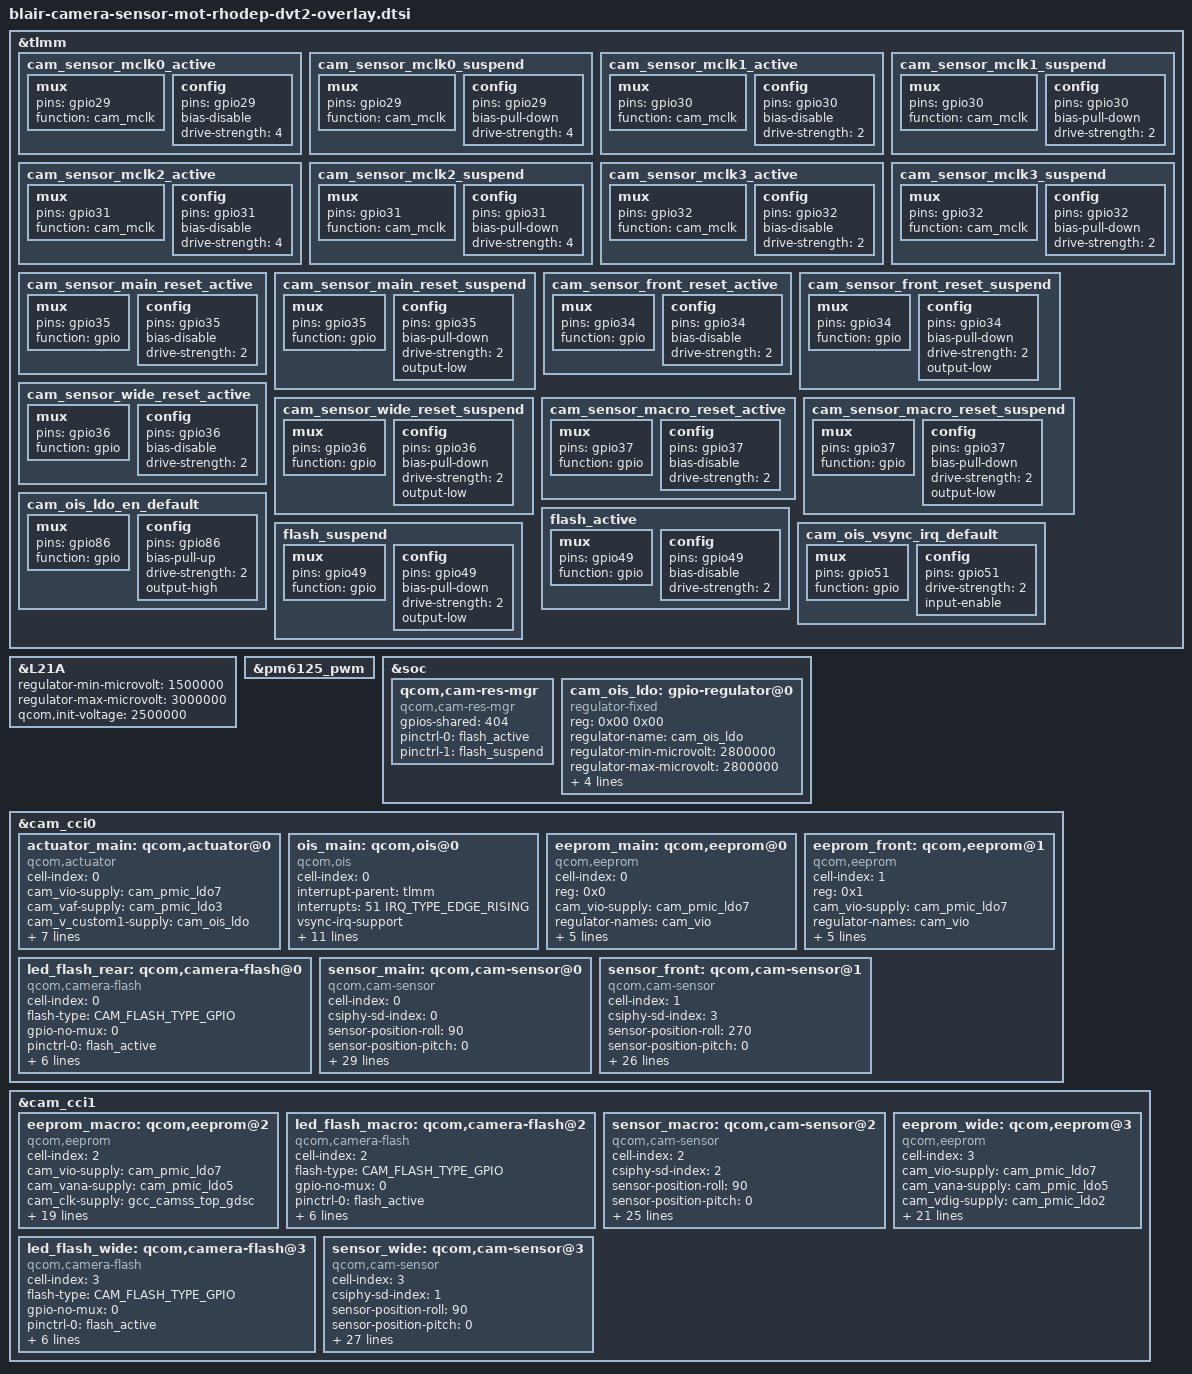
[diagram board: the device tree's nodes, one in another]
#include <dt-bindings/clock/qcom,gcc-blair.h>
#include <dt-bindings/msm/msm-camera.h>

/delete-node/ &cam_sensor_mclk0_active;
/delete-node/ &cam_sensor_mclk1_active;
/delete-node/ &cam_sensor_mclk2_active;
/delete-node/ &cam_sensor_mclk3_active;
/delete-node/ &cam_sensor_main_reset_active;
/delete-node/ &cam_sensor_front_reset_active;
/delete-node/ &cam_sensor_macro_reset_active;
/delete-node/ &cam_sensor_wide_reset_active;
/delete-node/ &flash_active;
/delete-node/ &cam_sensor_mclk0_suspend;
/delete-node/ &cam_sensor_mclk1_suspend;
/delete-node/ &cam_sensor_mclk2_suspend;
/delete-node/ &cam_sensor_mclk3_suspend;
/delete-node/ &cam_sensor_main_reset_suspend;
/delete-node/ &cam_sensor_front_reset_suspend;
/delete-node/ &cam_sensor_macro_reset_suspend;
/delete-node/ &cam_sensor_wide_reset_suspend;
/delete-node/ &flash_suspend;
/delete-node/ &cam_ois_ldo_en_default;
/delete-node/ &cam_ois_ldo;
/delete-node/ &actuator_main;
/delete-node/ &ois_main;
/delete-node/ &eeprom_main;
/delete-node/ &eeprom_front;
/delete-node/ &led_flash_rear;
/delete-node/ &sensor_main;
/delete-node/ &sensor_front;
/delete-node/ &eeprom_macro;
/delete-node/ &led_flash_macro;
/delete-node/ &sensor_macro;
/delete-node/ &eeprom_wide;
/delete-node/ &led_flash_wide;
/delete-node/ &sensor_wide;
/delete-node/ &cam_ois_vsync_irq_default;

&tlmm {
	cam_sensor_mclk0_active: cam_sensor_mclk0_active {
		mux {
			pins = "gpio29";
			function = "cam_mclk";
		};

		config {
			pins = "gpio29";
			bias-disable; /* No PULL */
			drive-strength = <4>; /* 2 MA */
		};
	};

	cam_sensor_mclk0_suspend: cam_sensor_mclk0_suspend {
		mux {
			pins = "gpio29";
			function = "cam_mclk";
		};

		config {
			pins = "gpio29";
			bias-pull-down; /* PULL DOWN */
			drive-strength = <4>; /* 2 MA */
		};
	};

	cam_sensor_mclk1_active: cam_sensor_mclk1_active {
		mux {
			pins = "gpio30";
			function = "cam_mclk";
		};

		config {
			pins = "gpio30";
			bias-disable; /* No PULL */
			drive-strength = <2>;
		};
	};

	cam_sensor_mclk1_suspend: cam_sensor_mclk1_suspend {
		mux {
			pins = "gpio30";
			function = "cam_mclk";
		};

		config {
			pins = "gpio30";
			bias-pull-down; /* PULL DOWN */
			drive-strength = <2>;
		};
	};

	cam_sensor_mclk2_active: cam_sensor_mclk2_active {
		mux {
			pins = "gpio31";
			function = "cam_mclk";
		};

		config {
			pins = "gpio31";
			bias-disable; /* No PULL */
			drive-strength = <4>;
		};
	};

	cam_sensor_mclk2_suspend: cam_sensor_mclk2_suspend {
		mux {
			pins = "gpio31";
			function = "cam_mclk";
		};

		config {
			pins = "gpio31";
			bias-pull-down; /* PULL DOWN */
			drive-strength = <4>;
		};
	};

	cam_sensor_mclk3_active: cam_sensor_mclk3_active {
		mux {
			pins = "gpio32";
			function = "cam_mclk";
		};

		config {
			pins = "gpio32";
			bias-disable; /* No PULL */
			drive-strength = <2>;
		};
	};

	cam_sensor_mclk3_suspend: cam_sensor_mclk3_suspend {
		mux {
			pins = "gpio32";
			function = "cam_mclk";
		};

		config {
			pins = "gpio32";
			bias-pull-down; /* PULL DOWN */
			drive-strength = <2>;
		};
	};

	cam_sensor_main_reset_active: cam_sensor_main_reset_active {
		mux {
			pins = "gpio35";
			function = "gpio";
		};

		config {
			pins = "gpio35";
			bias-disable; /* No PULL */
			drive-strength = <2>; /* 2 MA */
		};
	};

	cam_sensor_main_reset_suspend: cam_sensor_main_reset_suspend {
		mux {
			pins = "gpio35";
			function = "gpio";
		};

		config {
			pins = "gpio35";
			bias-pull-down; /* PULL DOWN */
			drive-strength = <2>; /* 2 MA */
			output-low;
		};
	};

	cam_sensor_front_reset_active: cam_sensor_front_reset_active {
		mux {
			pins = "gpio34";
			function = "gpio";
		};

		config {
			pins = "gpio34";
			bias-disable; /* No PULL */
			drive-strength = <2>; /* 2 MA */
		};
	};

	cam_sensor_front_reset_suspend: cam_sensor_front_reset_suspend {
		mux {
			pins = "gpio34";
			function = "gpio";
		};

		config {
			pins = "gpio34";
			bias-pull-down; /* PULL DOWN */
			drive-strength = <2>; /* 2 MA */
			output-low;
		};
	};

	cam_sensor_wide_reset_active: cam_sensor_wide_reset_active {
		mux {
			pins = "gpio36";
			function = "gpio";
		};

		config {
			pins = "gpio36";
			bias-disable; /* No PULL */
			drive-strength = <2>; /* 2 MA */
		};
	};

	cam_sensor_wide_reset_suspend: cam_sensor_wide_reset_suspend {
		mux {
			pins = "gpio36";
			function = "gpio";
		};

		config {
			pins = "gpio36";
			bias-pull-down; /* PULL DOWN */
			drive-strength = <2>; /* 2 MA */
			output-low;
		};
	};

	cam_sensor_macro_reset_active: cam_sensor_macro_reset_active {
		mux {
			pins = "gpio37";
			function = "gpio";
		};

		config {
			pins = "gpio37";
			bias-disable; /* No PULL */
			drive-strength = <2>; /* 2 MA */
		};
	};

	cam_sensor_macro_reset_suspend: cam_sensor_macro_reset_suspend {
		mux {
			pins = "gpio37";
			function = "gpio";
		};

		config {
			pins = "gpio37";
			bias-pull-down; /* PULL DOWN */
			drive-strength = <2>; /* 2 MA */
			output-low;
		};
	};
	cam_ois_ldo_en_default: cam_ois_ldo_en_default {
		mux {
			pins = "gpio86";
			function = "gpio";
		};
		config {
			pins = "gpio86";
			bias-pull-up; /* NO PULL */
			drive-strength = <2>; /* 2 MA */
			output-high;
		};
	};

	flash_active: flash_active {
		/* MCLK 0*/
		mux {
			pins = "gpio49";
			function = "gpio";
		};

		config {
			pins = "gpio49";
			bias-disable; /* No PULL */
			drive-strength = <2>; /* 2 MA */
		};
	};

	flash_suspend: flash_suspend {
		/* MCLK 0*/
		mux {
			pins = "gpio49";
			function = "gpio";
		};

		config {
			pins = "gpio49";
			bias-pull-down; /* PULL DOWN */
			drive-strength = <2>; /* 2 MA */
			output-low;
		};
	};

	cam_ois_vsync_irq_default: cam_ois_vsync_irq_default {
		mux {
			pins = "gpio51";
			function = "gpio";
		};
		config {
			pins = "gpio51";
			drive-strength = <2>;
			input-enable;
		};
	};
};

&L21A{
	regulator-min-microvolt = <1500000>;
	regulator-max-microvolt = <3000000>;
	qcom,init-voltage = <2500000>;
	status = "okay";
};

&pm6125_pwm {
 status = "ok";
};

&soc {
	qcom,cam-res-mgr {
		compatible = "qcom,cam-res-mgr";
		status = "ok";
		gpios-shared = <404>;
		pinctrl-names = "flash_active", "flash_suspend";
		pinctrl-0 = <&flash_active>;
		pinctrl-1 = <&flash_suspend>;
	};

	cam_ois_ldo: gpio-regulator@0{
		compatible = "regulator-fixed";
		reg = <0x00 0x00>;
		regulator-name = "cam_ois_ldo";
		regulator-min-microvolt = <2800000>;
		regulator-max-microvolt = <2800000>;
		regulator-enable-ramp-delay = <233>;
		enable-active-high;
		gpio = <&tlmm 86 0>;
		pinctrl-names = "default";
		pinctrl-0 = <&cam_ois_ldo_en_default>;
	};
};

&cam_cci0 {
	actuator_main: qcom,actuator@0 {
		cell-index = <0>;
		compatible = "qcom,actuator";
		cam_vio-supply = <&cam_pmic_ldo7>;
		cam_vaf-supply = <&cam_pmic_ldo3>;
		cam_v_custom1-supply = <&cam_ois_ldo>;
		regulator-names = "cam_vio", "cam_vaf", "cam_v_custom1";
		rgltr-cntrl-support;
		rgltr-min-voltage = <1800000 2800000 2800000>;
		rgltr-max-voltage = <1805000 2805000 2805000>;
		rgltr-load-current = <120000 100000 100000>;
		cci-master = <1>;
		status = "ok";
	};

	ois_main: qcom,ois@0 {
		cell-index = <0>;
		compatible = "qcom,ois";
		interrupt-parent = <&tlmm>;
		interrupts = <51 IRQ_TYPE_EDGE_RISING>;
		vsync-irq-support;
		pinctrl-names = "default";
		pinctrl-0 = <&cam_ois_vsync_irq_default>;
		cam_vio-supply = <&cam_pmic_ldo7>;
		cam_vaf-supply = <&cam_pmic_ldo3>;
		cam_v_custom1-supply = <&cam_ois_ldo>;
		regulator-names = "cam_vio", "cam_vaf", "cam_v_custom1";
		rgltr-cntrl-support;
		rgltr-min-voltage = <1800000 2800000 2800000>;
		rgltr-max-voltage = <1805000 2805000 2800000>;
		rgltr-load-current = <120000 100000 100000>;
		cci-master = <1>;
		status = "ok";
	};

	eeprom_main: qcom,eeprom@0 {
		cell-index = <0>;
		reg = <0x0>;
		compatible = "qcom,eeprom";
		cam_vio-supply = <&cam_pmic_ldo7>;
		regulator-names = "cam_vio";
		rgltr-cntrl-support;
		rgltr-min-voltage = <1800000>;
		rgltr-max-voltage = <1805000>;
		rgltr-load-current = <120000>;
		cci-master = <1>;
		status = "ok";
	};

	eeprom_front: qcom,eeprom@1 {
		cell-index = <1>;
		reg = <0x1>;
		compatible = "qcom,eeprom";
		cam_vio-supply = <&cam_pmic_ldo7>;
		regulator-names = "cam_vio";
		rgltr-cntrl-support;
		rgltr-min-voltage = <1800000>;
		rgltr-max-voltage = <1805000>;
		rgltr-load-current = <3000>;
		cci-master = <0>;
		status = "ok";
	};

	led_flash_rear: qcom,camera-flash@0 {
		cell-index = <0>;
		compatible = "qcom,camera-flash";
		flash-type = <CAM_FLASH_TYPE_GPIO>;
		gpio-no-mux = <0>;
		pinctrl-names = "cam_default", "cam_suspend";
		pinctrl-0 = <&flash_active>;
		pinctrl-1 = <&flash_suspend>;
		gpios = <&tlmm 49 0>;
		gpio-custom1 = <0>;
		gpio-req-tbl-num = <0>;
		gpio-req-tbl-flags = <0>;
		gpio-req-tbl-label = "CUSTOM_GPIO1";
		status = "ok";
	};

	sensor_main: qcom,cam-sensor@0 {
		cell-index = <0>;
		compatible = "qcom,cam-sensor";
		csiphy-sd-index = <0>;
		sensor-position-roll = <90>;
		sensor-position-pitch = <0>;
		sensor-position-yaw = <180>;
		actuator-src = <&actuator_main>;
		eeprom-src = <&eeprom_main>;
		ois-src = <&ois_main>;
		led-flash-src = <&led_flash_rear>;
		cam_vio-supply = <&cam_pmic_ldo7>;
		cam_vana-supply = <&cam_pmic_ldo4>;
		cam_vdig-supply = <&cam_pmic_ldo1>;
		cam_clk-supply = <&gcc_camss_top_gdsc>;
		regulator-names = "cam_vio", "cam_vana", "cam_vdig",
			"cam_clk";
		rgltr-cntrl-support;
		rgltr-min-voltage = <1800000 2800000 1050000 0>;
		rgltr-max-voltage = <1805000 2805000 1100000 0>;
		rgltr-load-current = <120000 80000 1200000 0>;
		gpio-no-mux = <0>;
		pinctrl-names = "cam_default", "cam_suspend";
		pinctrl-0 = <&cam_sensor_mclk1_active
				&cam_sensor_main_reset_active>;
		pinctrl-1 = <&cam_sensor_mclk1_suspend
				&cam_sensor_main_reset_suspend>;
		gpios = <&tlmm 30 0>,
			<&tlmm 35 0>;
		gpio-reset = <1>;
		gpio-req-tbl-num = <0 1>;
		gpio-req-tbl-flags = <1 0>;
		gpio-req-tbl-label = "CAMIF_MCLK1",
					"CAM_RM_RST";
		cci-master = <1>;
		status = "ok";
		clocks = <&gcc GCC_CAMSS_MCLK1_CLK>;
		clock-names = "cam_clk";
		clock-cntl-level = "turbo";
		clock-rates = <24000000>;
	};
	sensor_front: qcom,cam-sensor@1 {
		cell-index = <1>;
		compatible = "qcom,cam-sensor";
		csiphy-sd-index = <3>;
		sensor-position-roll = <270>;
		sensor-position-pitch = <0>;
		sensor-position-yaw = <0>;
		eeprom-src = <&eeprom_front>;
		cam_vio-supply = <&cam_pmic_ldo7>;
		cam_vana-supply = <&cam_pmic_ldo6>;
		cam_vdig-supply = <&L21A>;
		cam_clk-supply = <&gcc_camss_top_gdsc>;
		regulator-names = "cam_vio", "cam_vana", "cam_vdig",
			"cam_clk";
		rgltr-cntrl-support;
		rgltr-min-voltage = <1800000 2800000 2500000 0>;
		rgltr-max-voltage = <1805000 2805000 2500000 0>;
		rgltr-load-current = <120000 80000 2500000 0>;
		gpio-no-mux = <0>;
		pinctrl-names = "cam_default", "cam_suspend";
		pinctrl-0 = <&cam_sensor_mclk0_active
				&cam_sensor_front_reset_active>;
		pinctrl-1 = <&cam_sensor_mclk0_suspend
				&cam_sensor_front_reset_suspend>;
		gpios = <&tlmm 31 0>,
			<&tlmm 34 0>;
		gpio-reset = <1>;
		gpio-req-tbl-num = <0 1>;
		gpio-req-tbl-flags = <1 0>;
		gpio-req-tbl-label = "CAMIF_MCLK0",
					"CAM_FW_RST";
		cci-master = <0>;
		status = "ok";
		clocks = <&gcc GCC_CAMSS_MCLK0_CLK>;
		clock-names = "cam_clk";
		clock-cntl-level = "turbo";
		clock-rates = <24000000>;
	};
};

&cam_cci1 {
	eeprom_macro: qcom,eeprom@2 {
		cell-index = <2>;
		compatible = "qcom,eeprom";
		cam_vio-supply = <&cam_pmic_ldo7>;
		cam_vana-supply = <&cam_pmic_ldo5>;
		cam_clk-supply = <&gcc_camss_top_gdsc>;
		regulator-names = "cam_vio", "cam_vana",
			"cam_clk";
		rgltr-cntrl-support;
		rgltr-min-voltage = <1800000 2800000 0>;
		rgltr-max-voltage = <1805000 2805000 0>;
		rgltr-load-current = <120000 80000 0>;
		gpio-no-mux = <0>;
		pinctrl-names = "cam_default", "cam_suspend";
		pinctrl-0 = <&cam_sensor_mclk3_active
				&cam_sensor_macro_reset_active>;
		pinctrl-1 = <&cam_sensor_mclk3_suspend
				&cam_sensor_macro_reset_suspend>;
		gpios = <&tlmm 32 0>,
			<&tlmm 37 0>;
		gpio-reset = <1>;
		gpio-req-tbl-num = <0 1>;
		gpio-req-tbl-flags = <1 0>;
		gpio-req-tbl-label = "CAMIF_MCLK3",
					"CAM_RW_RST";
		cci-master = <0>;
		status = "ok";
		clocks = <&gcc GCC_CAMSS_MCLK3_CLK>;
		clock-names = "cam_clk";
		clock-cntl-level = "turbo";
		clock-rates = <24000000>;
	};

	led_flash_macro: qcom,camera-flash@2 {
		cell-index = <2>;
		compatible = "qcom,camera-flash";
		flash-type = <CAM_FLASH_TYPE_GPIO>;
		gpio-no-mux = <0>;
		pinctrl-names = "cam_default", "cam_suspend";
		pinctrl-0 = <&flash_active>;
		pinctrl-1 = <&flash_suspend>;
		gpios = <&tlmm 49 0>;
		gpio-custom1 = <0>;
		gpio-req-tbl-num = <0>;
		gpio-req-tbl-flags = <0>;
		gpio-req-tbl-label = "CUSTOM_GPIO1";
		status = "ok";
	};
	sensor_macro: qcom,cam-sensor@2 {
		cell-index = <2>;
		compatible = "qcom,cam-sensor";
		csiphy-sd-index = <2>;
		sensor-position-roll = <90>;
		sensor-position-pitch = <0>;
		sensor-position-yaw = <180>;
		led-flash-src = <&led_flash_macro>;
		eeprom-src = <&eeprom_macro>;
		cam_vio-supply = <&cam_pmic_ldo7>;
		cam_vana-supply = <&cam_pmic_ldo5>;
		cam_clk-supply = <&gcc_camss_top_gdsc>;
		regulator-names = "cam_vio", "cam_vana",
			"cam_clk";
		rgltr-cntrl-support;
		rgltr-min-voltage = <1800000 2800000 0>;
		rgltr-max-voltage = <1805000 2805000 0>;
		rgltr-load-current = <120000 80000 0>;
		gpio-no-mux = <0>;
		pinctrl-names = "cam_default", "cam_suspend";
		pinctrl-0 = <&cam_sensor_mclk3_active
				&cam_sensor_macro_reset_active>;
		pinctrl-1 = <&cam_sensor_mclk3_suspend
				&cam_sensor_macro_reset_suspend>;
		gpios = <&tlmm 32 0>,
			<&tlmm 37 0>;
		gpio-reset = <1>;
		gpio-req-tbl-num = <0 1>;
		gpio-req-tbl-flags = <1 0>;
		gpio-req-tbl-label = "CAMIF_MCLK3",
					"CAM_RW_RST";
		cci-master = <0>;
		status = "ok";
		clocks = <&gcc GCC_CAMSS_MCLK3_CLK>;
		clock-names = "cam_clk";
		clock-cntl-level = "turbo";
		clock-rates = <24000000>;
	};

	eeprom_wide: qcom,eeprom@3 {
		cell-index = <3>;
		compatible = "qcom,eeprom";
		cam_vio-supply = <&cam_pmic_ldo7>;
		cam_vana-supply = <&cam_pmic_ldo5>;
		cam_vdig-supply = <&cam_pmic_ldo2>;
		cam_clk-supply = <&gcc_camss_top_gdsc>;
		regulator-names = "cam_vio", "cam_vana", "cam_vdig",
			"cam_clk";
		rgltr-cntrl-support;
		rgltr-min-voltage = <1800000 2800000 1200000 0>;
		rgltr-max-voltage = <1805000 2805000 1205000 0>;
		rgltr-load-current = <120000 80000 1200000 0>;
		gpio-no-mux = <0>;
		pinctrl-names = "cam_default", "cam_suspend";
		pinctrl-0 = <&cam_sensor_mclk2_active
				&cam_sensor_wide_reset_active>;
		pinctrl-1 = <&cam_sensor_mclk2_suspend
				&cam_sensor_wide_reset_suspend>;
		gpios = <&tlmm 31 0>,
			<&tlmm 36 0>;
		gpio-reset = <1>;
		gpio-req-tbl-num = <0 1>;
		gpio-req-tbl-flags = <1 0>;
		gpio-req-tbl-label = "CAMIF_MCLK2",
					"CAM_RW_RST";
		cci-master = <0>;
		status = "ok";
		clocks = <&gcc GCC_CAMSS_MCLK2_CLK>;
		clock-names = "cam_clk";
		clock-cntl-level = "turbo";
		clock-rates = <24000000>;
	};

	led_flash_wide: qcom,camera-flash@3 {
		cell-index = <3>;
		compatible = "qcom,camera-flash";
		flash-type = <CAM_FLASH_TYPE_GPIO>;
		gpio-no-mux = <0>;
		pinctrl-names = "cam_default", "cam_suspend";
		pinctrl-0 = <&flash_active>;
		pinctrl-1 = <&flash_suspend>;
		gpios = <&tlmm 49 0>;
		gpio-custom1 = <0>;
		gpio-req-tbl-num = <0>;
		gpio-req-tbl-flags = <0>;
		gpio-req-tbl-label = "CUSTOM_GPIO1";
		status = "ok";
	};
	sensor_wide: qcom,cam-sensor@3 {
		cell-index = <3>;
		compatible = "qcom,cam-sensor";
		csiphy-sd-index = <1>;
		sensor-position-roll = <90>;
		sensor-position-pitch = <0>;
		sensor-position-yaw = <180>;
		led-flash-src = <&led_flash_wide>;
		eeprom-src = <&eeprom_wide>;
		cam_vio-supply = <&cam_pmic_ldo7>;
		cam_vana-supply = <&cam_pmic_ldo5>;
		cam_vdig-supply = <&cam_pmic_ldo2>;
		cam_clk-supply = <&gcc_camss_top_gdsc>;
		regulator-names = "cam_vio", "cam_vana", "cam_vdig",
			"cam_clk";
		rgltr-cntrl-support;
		rgltr-min-voltage = <1800000 2800000 1200000 0>;
		rgltr-max-voltage = <1805000 2805000 1205000 0>;
		rgltr-load-current = <120000 80000 1200000 0>;
		gpio-no-mux = <0>;
		pinctrl-names = "cam_default", "cam_suspend";
		pinctrl-0 = <&cam_sensor_mclk2_active
				&cam_sensor_wide_reset_active>;
		pinctrl-1 = <&cam_sensor_mclk2_suspend
				&cam_sensor_wide_reset_suspend>;
		gpios = <&tlmm 31 0>,
			<&tlmm 36 0>;
		gpio-reset = <1>;
		gpio-req-tbl-num = <0 1>;
		gpio-req-tbl-flags = <1 0>;
		gpio-req-tbl-label = "CAMIF_MCLK2",
					"CAM_RW_RST";
		cci-master = <0>;
		status = "ok";
		clocks = <&gcc GCC_CAMSS_MCLK2_CLK>;
		clock-names = "cam_clk";
		clock-cntl-level = "turbo";
		clock-rates = <24000000>;
	};


};
